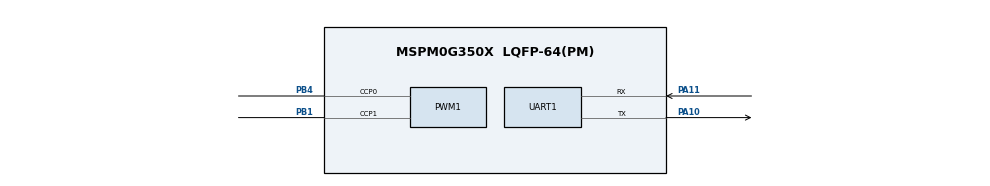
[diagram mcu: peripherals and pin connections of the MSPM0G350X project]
/**
 * @cliArgs --device "MSPM0G350X" --part "Default" --package "LQFP-64(PM)" --product "mspm0_sdk@2.10.00.04"
 * @versions {"tool":"1.26.2+4477"}
 */

/**
 * Import the modules used in this configuration.
 */
const ADC12         = scripting.addModule("/ti/driverlib/ADC12", {}, false);
const ADC121        = ADC12.addInstance();
const GPIO          = scripting.addModule("/ti/driverlib/GPIO", {}, false);
const GPIO1         = GPIO.addInstance();
const GPIO2         = GPIO.addInstance();
const GPIO3         = GPIO.addInstance();
const GPIO4         = GPIO.addInstance();
const PWM           = scripting.addModule("/ti/driverlib/PWM", {}, false);
const PWM1          = PWM.addInstance();
const SYSCTL        = scripting.addModule("/ti/driverlib/SYSCTL");
const UART          = scripting.addModule("/ti/driverlib/UART", {}, false);
const UART1         = UART.addInstance();
const ProjectConfig = scripting.addModule("/ti/project_config/ProjectConfig");

/**
 * Write custom configuration values to the imported modules.
 */
ADC121.$name                          = "LINE_ADC";
ADC121.sampClkSrc                     = "DL_ADC12_CLOCK_ULPCLK";
ADC121.sampClkDiv                     = "DL_ADC12_CLOCK_DIVIDE_8";
ADC121.adcMem0chansel                 = "DL_ADC12_INPUT_CHAN_3";
ADC121.sampleTime0                    = "10 us";
ADC121.powerDownMode                  = "DL_ADC12_POWER_DOWN_MODE_MANUAL";
ADC121.repeatMode                     = true;
ADC121.configureDMA                   = true;
ADC121.sampCnt                        = 1;
ADC121.enabledDMATriggers             = ["DL_ADC12_DMA_MEM0_RESULT_LOADED"];
ADC121.peripheral.$assign             = "ADC0";
ADC121.peripheral.adcPin3.$assign     = "PA24";
ADC121.adcPin3Config.$name            = "ti_driverlib_gpio_GPIOPinGeneric0";
ADC121.DMA_CHANNEL.$name              = "LINE_DMA";
ADC121.DMA_CHANNEL.addressMode        = "f2b";
ADC121.DMA_CHANNEL.srcLength          = "HALF_WORD";
ADC121.DMA_CHANNEL.dstLength          = "HALF_WORD";
ADC121.DMA_CHANNEL.transferSize       = 8;
ADC121.DMA_CHANNEL.enableInterrupt    = true;
ADC121.DMA_CHANNEL.peripheral.$assign = "DMA_CH0";

const Board = scripting.addModule("/ti/driverlib/Board", {}, false);

GPIO1.$name                          = "GPIO_OUT";
GPIO1.associatedPins.create(7);
GPIO1.associatedPins[0].$name        = "AIN1";
GPIO1.associatedPins[0].assignedPort = "PORTA";
GPIO1.associatedPins[0].assignedPin  = "13";
GPIO1.associatedPins[1].$name        = "AIN2";
GPIO1.associatedPins[1].assignedPort = "PORTA";
GPIO1.associatedPins[1].assignedPin  = "12";
GPIO1.associatedPins[2].$name        = "BIN1";
GPIO1.associatedPins[2].assignedPort = "PORTB";
GPIO1.associatedPins[2].assignedPin  = "0";
GPIO1.associatedPins[3].$name        = "BIN2";
GPIO1.associatedPins[3].assignedPort = "PORTB";
GPIO1.associatedPins[3].assignedPin  = "8";
GPIO1.associatedPins[4].$name        = "LINE_AD2";
GPIO1.associatedPins[4].assignedPort = "PORTB";
GPIO1.associatedPins[4].assignedPin  = "24";
GPIO1.associatedPins[5].$name        = "LINE_AD1";
GPIO1.associatedPins[5].assignedPort = "PORTB";
GPIO1.associatedPins[5].assignedPin  = "25";
GPIO1.associatedPins[6].$name        = "LINE_AD0";
GPIO1.associatedPins[6].assignedPort = "PORTB";
GPIO1.associatedPins[6].assignedPin  = "20";

GPIO2.$name                          = "GPIO_ENCODER";
GPIO2.associatedPins.create(4);
GPIO2.associatedPins[0].$name        = "E1A";
GPIO2.associatedPins[0].assignedPort = "PORTA";
GPIO2.associatedPins[0].assignedPin  = "15";
GPIO2.associatedPins[0].direction    = "INPUT";
GPIO2.associatedPins[1].$name        = "E1B";
GPIO2.associatedPins[1].assignedPort = "PORTA";
GPIO2.associatedPins[1].assignedPin  = "16";
GPIO2.associatedPins[1].direction    = "INPUT";
GPIO2.associatedPins[2].$name        = "E2A";
GPIO2.associatedPins[2].assignedPort = "PORTA";
GPIO2.associatedPins[2].assignedPin  = "17";
GPIO2.associatedPins[2].direction    = "INPUT";
GPIO2.associatedPins[3].$name        = "E2B";
GPIO2.associatedPins[3].assignedPort = "PORTB";
GPIO2.associatedPins[3].assignedPin  = "9";
GPIO2.associatedPins[3].direction    = "INPUT";

GPIO3.$name                              = "GPIO_KEY_USER";
GPIO3.associatedPins[0].$name            = "KEY_USER";
GPIO3.associatedPins[0].assignedPort     = "PORTB";
GPIO3.associatedPins[0].assignedPin      = "21";
GPIO3.associatedPins[0].direction        = "INPUT";
GPIO3.associatedPins[0].internalResistor = "PULL_UP";

GPIO4.$name                          = "GPIO_BUZZER";
GPIO4.associatedPins[0].$name        = "BUZZER";
GPIO4.associatedPins[0].assignedPort = "PORTA";
GPIO4.associatedPins[0].assignedPin  = "2";
GPIO4.associatedPins[0].ioStructure  = "SD";

PWM1.$name                              = "MOTOR_PWM";
PWM1.timerCount                         = 1600;
PWM1.enableShadowLoad                   = true;
PWM1.peripheral.$assign                 = "TIMA1";
PWM1.peripheral.ccp0Pin.$assign         = "PB4";
PWM1.peripheral.ccp1Pin.$assign         = "PB1";
PWM1.PWM_CHANNEL_0.$name                = "PWMA";
PWM1.PWM_CHANNEL_1.$name                = "PWMB";
PWM1.ccp0PinConfig.$name                = "ti_driverlib_gpio_GPIOPinGeneric1";
PWM1.ccp0PinConfig.direction            = scripting.forceWrite("OUTPUT");
PWM1.ccp0PinConfig.hideOutputInversion  = scripting.forceWrite(false);
PWM1.ccp0PinConfig.onlyInternalResistor = scripting.forceWrite(false);
PWM1.ccp0PinConfig.passedPeripheralType = scripting.forceWrite("Digital");
PWM1.ccp1PinConfig.$name                = "ti_driverlib_gpio_GPIOPinGeneric2";
PWM1.ccp1PinConfig.direction            = scripting.forceWrite("OUTPUT");
PWM1.ccp1PinConfig.hideOutputInversion  = scripting.forceWrite(false);
PWM1.ccp1PinConfig.onlyInternalResistor = scripting.forceWrite(false);
PWM1.ccp1PinConfig.passedPeripheralType = scripting.forceWrite("Digital");

SYSCTL.forceDefaultClkConfig = true;

UART1.$name                    = "UART_0";
UART1.peripheral.$assign       = "UART0";
UART1.peripheral.rxPin.$assign = "PA11";
UART1.peripheral.txPin.$assign = "PA10";
UART1.txPinConfig.$name        = "ti_driverlib_gpio_GPIOPinGeneric3";
UART1.rxPinConfig.$name        = "ti_driverlib_gpio_GPIOPinGeneric4";

ProjectConfig.deviceSpin = "MSPM0G3507";

/**
 * Pinmux solution for unlocked pins/peripherals. This ensures that minor changes to the automatic solver in a future
 * version of the tool will not impact the pinmux you originally saw.  These lines can be completely deleted in order to
 * re-solve from scratch.
 */
Board.peripheral.$suggestSolution            = "DEBUGSS";
Board.peripheral.swclkPin.$suggestSolution   = "PA20";
Board.peripheral.swdioPin.$suggestSolution   = "PA19";
GPIO1.associatedPins[0].pin.$suggestSolution = "PA13";
GPIO1.associatedPins[1].pin.$suggestSolution = "PA12";
GPIO1.associatedPins[2].pin.$suggestSolution = "PB0";
GPIO1.associatedPins[3].pin.$suggestSolution = "PB8";
GPIO1.associatedPins[4].pin.$suggestSolution = "PB24";
GPIO1.associatedPins[5].pin.$suggestSolution = "PB25";
GPIO1.associatedPins[6].pin.$suggestSolution = "PB20";
GPIO2.associatedPins[0].pin.$suggestSolution = "PA15";
GPIO2.associatedPins[1].pin.$suggestSolution = "PA16";
GPIO2.associatedPins[2].pin.$suggestSolution = "PA17";
GPIO2.associatedPins[3].pin.$suggestSolution = "PB9";
GPIO3.associatedPins[0].pin.$suggestSolution = "PB21";
GPIO4.associatedPins[0].pin.$suggestSolution = "PA2";
SYSCTL.peripheral.$suggestSolution           = "SYSCTL";
